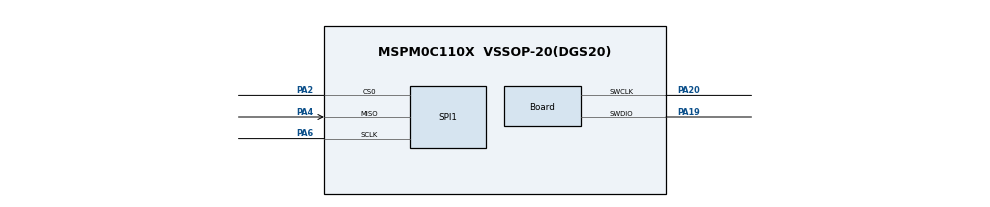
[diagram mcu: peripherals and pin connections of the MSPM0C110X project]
/**
 * @cliArgs --device "MSPM0C110X" --part "Default" --package "VSSOP-20(DGS20)" --product "mspm0_sdk@2.07.00.06"
 * @versions {"tool":"1.25.0+4268"}
 */

/**
 * Import the modules used in this configuration.
 */
const GPIO   = scripting.addModule("/ti/driverlib/GPIO", {}, false);
const GPIO1  = GPIO.addInstance();
const SPI    = scripting.addModule("/ti/driverlib/SPI", {}, false);
const SPI1   = SPI.addInstance();
const SYSCTL = scripting.addModule("/ti/driverlib/SYSCTL");

/**
 * Write custom configuration values to the imported modules.
 */
GPIO1.$name                          = "GPIO_LEDS";
GPIO1.associatedPins[0].$name        = "USER_LED_1";
GPIO1.associatedPins[0].initialValue = "SET";
GPIO1.associatedPins[0].assignedPin  = "22";

const Board                       = scripting.addModule("/ti/driverlib/Board", {}, false);
Board.peripheral.$assign          = "DEBUGSS";
Board.peripheral.swclkPin.$assign = "PA20";
Board.peripheral.swdioPin.$assign = "PA19";

SPI1.$name                      = "SPI_0";
SPI1.targetBitRate              = 100000;
SPI1.enabledInterrupts          = ["RX"];
SPI1.rxFifoThreshold            = "DL_SPI_RX_FIFO_LEVEL_ONE_FRAME";
SPI1.txFifoThreshold            = "DL_SPI_TX_FIFO_LEVEL_EMPTY";
SPI1.peripheral.sclkPin.$assign = "PA6";
SPI1.peripheral.misoPin.$assign = "PA4";
SPI1.peripheral.cs0Pin.$assign  = "PA2";
SPI1.sclkPinConfig.$name        = "ti_driverlib_gpio_GPIOPinGeneric0";
SPI1.mosiPinConfig.$name        = "ti_driverlib_gpio_GPIOPinGeneric1";
SPI1.misoPinConfig.$name        = "ti_driverlib_gpio_GPIOPinGeneric2";
SPI1.cs0PinConfig.$name         = "ti_driverlib_gpio_GPIOPinGeneric3";

SYSCTL.clockTreeEn = true;

/**
 * Pinmux solution for unlocked pins/peripherals. This ensures that minor changes to the automatic solver in a future
 * version of the tool will not impact the pinmux you originally saw.  These lines can be completely deleted in order to
 * re-solve from scratch.
 */
GPIO1.associatedPins[0].pin.$suggestSolution = "PA22";
SPI1.peripheral.$suggestSolution             = "SPI0";
SPI1.peripheral.mosiPin.$suggestSolution     = "PA18";
